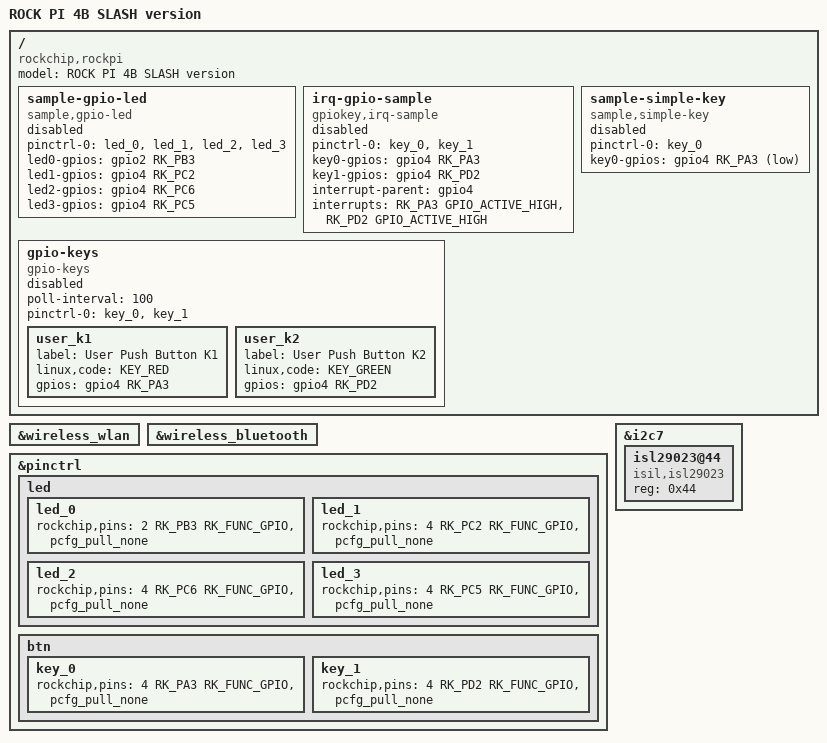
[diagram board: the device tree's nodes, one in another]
/*
 * Copyright (c) 2016 Fuzhou Rockchip Electronics Co., Ltd
 *
 * This file is dual-licensed: you can use it either under the terms
 * of the GPL or the X11 license, at your option. Note that this dual
 * licensing only applies to this file, and not this project as a
 * whole.
 *
 *  a) This file is free software; you can redistribute it and/or
 *     modify it under the terms of the GNU General Public License as
 *     published by the Free Software Foundation; either version 2 of the
 *     License, or (at your option) any later version.
 *
 *     This file is distributed in the hope that it will be useful,
 *     but WITHOUT ANY WARRANTY; without even the implied warranty of
 *     MERCHANTABILITY or FITNESS FOR A PARTICULAR PURPOSE.  See the
 *     GNU General Public License for more details.
 *
 * Or, alternatively,
 *
 *  b) Permission is hereby granted, free of charge, to any person
 *     obtaining a copy of this software and associated documentation
 *     files (the "Software"), to deal in the Software without
 *     restriction, including without limitation the rights to use,
 *     copy, modify, merge, publish, distribute, sublicense, and/or
 *     sell copies of the Software, and to permit persons to whom the
 *     Software is furnished to do so, subject to the following
 *     conditions:
 *
 *     The above copyright notice and this permission notice shall be
 *     included in all copies or substantial portions of the Software.
 *
 *     THE SOFTWARE IS PROVIDED "AS IS", WITHOUT WARRANTY OF ANY KIND,
 *     EXPRESS OR IMPLIED, INCLUDING BUT NOT LIMITED TO THE WARRANTIES
 *     OF MERCHANTABILITY, FITNESS FOR A PARTICULAR PURPOSE AND
 *     NONINFRINGEMENT. IN NO EVENT SHALL THE AUTHORS OR COPYRIGHT
 *     HOLDERS BE LIABLE FOR ANY CLAIM, DAMAGES OR OTHER LIABILITY,
 *     WHETHER IN AN ACTION OF CONTRACT, TORT OR OTHERWISE, ARISING
 *     FROM, OUT OF OR IN CONNECTION WITH THE SOFTWARE OR THE USE OR
 *     OTHER DEALINGS IN THE SOFTWARE.
 */

/dts-v1/;

#include "rk3399-rock-pi-4.dtsi"

/ {

	model = "ROCK PI 4B SLASH version";
	compatible = "rockchip,rockpi","rockchip,rk3399";

	sample-gpio-led {
		status = "disabled";
		compatible = "sample,gpio-led";
		pinctrl-names = "default";
		pinctrl-0 = <&led_0 &led_1 &led_2 &led_3>;

		led0-gpios = <&gpio2 RK_PB3 GPIO_ACTIVE_HIGH>;
		led1-gpios = <&gpio4 RK_PC2 GPIO_ACTIVE_HIGH>;
		led2-gpios = <&gpio4 RK_PC6 GPIO_ACTIVE_HIGH>;
		led3-gpios = <&gpio4 RK_PC5 GPIO_ACTIVE_HIGH>;
	};

	irq-gpio-sample {
		status = "disabled";
		compatible = "gpiokey,irq-sample";
		pinctrl-names = "default";
		pinctrl-0 = <&key_0 &key_1>;
		key0-gpios = <&gpio4 RK_PA3 GPIO_ACTIVE_HIGH>;
		key1-gpios = <&gpio4 RK_PD2 GPIO_ACTIVE_HIGH>;
		interrupt-parent = <&gpio4>;
		interrupts = <RK_PA3 GPIO_ACTIVE_HIGH>, <RK_PD2 GPIO_ACTIVE_HIGH>;
	};

	sample-simple-key {
		status = "disabled";
		compatible = "sample,simple-key";
		pinctrl-names = "default";
		pinctrl-0 = <&key_0>;
		key0-gpios = <&gpio4 RK_PA3 GPIO_ACTIVE_LOW>;
	};

	gpio-keys {
		compatible = "gpio-keys";
		poll-interval = <100>;
		status = "disabled";

		pinctrl-names = "default";
		pinctrl-0 = <&key_0 &key_1>;

		user_k1 {
			label = "User Push Button K1";
			linux,code = <KEY_RED>;
			gpios = <&gpio4 RK_PA3 GPIO_ACTIVE_HIGH>;
		};

		user_k2 {
			label = "User Push Button K2";
			linux,code = <KEY_GREEN>;
			gpios = <&gpio4 RK_PD2 GPIO_ACTIVE_HIGH>;
		};
	};

};

&wireless_wlan {
	status = "okay";
};

&wireless_bluetooth {
	status = "okay";
};

&pinctrl {
	led {
		led_0: led_0 {
			rockchip,pins = <2 RK_PB3 RK_FUNC_GPIO &pcfg_pull_none>;
		};
		led_1: led_1 {
			rockchip,pins = <4 RK_PC2 RK_FUNC_GPIO &pcfg_pull_none>;
		};
		led_2: led_2 {
			rockchip,pins = <4 RK_PC6 RK_FUNC_GPIO &pcfg_pull_none>;
		};
		led_3: led_3 {
			rockchip,pins = <4 RK_PC5 RK_FUNC_GPIO &pcfg_pull_none>;
		};
	};

	btn {
		key_0: key_0 {
			rockchip,pins = <4 RK_PA3 RK_FUNC_GPIO &pcfg_pull_none>;
		};
		key_1: key_1 {
			rockchip,pins = <4 RK_PD2 RK_FUNC_GPIO &pcfg_pull_none>;
		};
	};
};

&i2c7 {
	status = "okay";
	isl29023@44 {
		status = "okay";
		compatible = "isil,isl29023";
		reg = <0x44>;
	};
};
